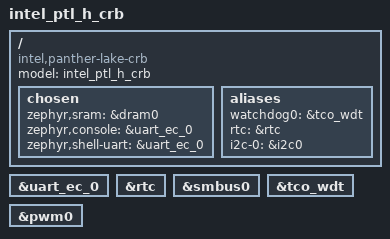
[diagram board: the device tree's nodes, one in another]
/*
 * Copyright (c) 2025 Intel Corporation
 * SPDX-License-Identifier: Apache-2.0
 */

/dts-v1/;

#include <mem.h>

#define DT_DRAM_SIZE		DT_SIZE_M(2048)

#include <intel/panther_lake_h.dtsi>

/ {
	model = "intel_ptl_h_crb";
	compatible = "intel,panther-lake-crb";

	chosen {
		zephyr,sram = &dram0;
		zephyr,console = &uart_ec_0;
		zephyr,shell-uart = &uart_ec_0;
	};

	aliases {
		watchdog0 = &tco_wdt;
		rtc = &rtc;
		i2c-0 = &i2c0;
	};
};

&uart_ec_0 {
	status = "okay";
};

&rtc {
	status = "okay";
};

&smbus0 {
	status = "okay";
};

&tco_wdt {
	status = "okay";
};

&pwm0 {
	status = "okay";
};
